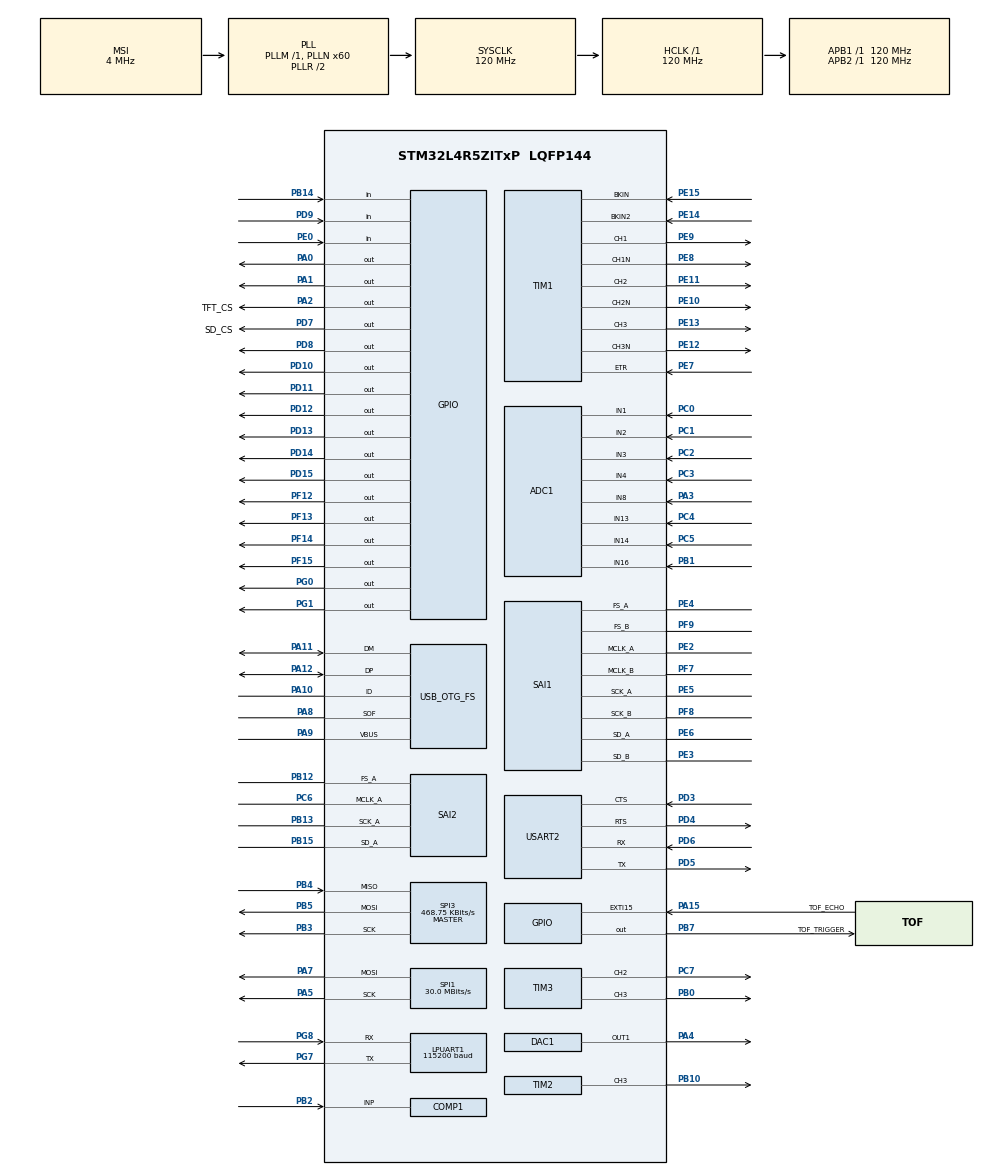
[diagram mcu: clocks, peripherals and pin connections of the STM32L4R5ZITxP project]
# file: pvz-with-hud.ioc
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ADC1.Channel-0\#ChannelRegularConversion=ADC_CHANNEL_1
ADC1.NbrOfConversionFlag=1
ADC1.OffsetNumber-0\#ChannelRegularConversion=ADC_OFFSET_NONE
ADC1.Rank-0\#ChannelRegularConversion=1
ADC1.SamplingTime-0\#ChannelRegularConversion=ADC_SAMPLETIME_2CYCLES_5
ADC1.master=1
DAC1.DAC_Trigger-DAC_OUT1=DAC_TRIGGER_T6_TRGO
Dma.DAC1_CH1.4.Direction=DMA_MEMORY_TO_PERIPH
Dma.DAC1_CH1.4.EventEnable=DISABLE
Dma.DAC1_CH1.4.Instance=DMA1_Channel5
Dma.DAC1_CH1.4.MemDataAlignment=DMA_MDATAALIGN_HALFWORD
Dma.DAC1_CH1.4.MemInc=DMA_MINC_ENABLE
Dma.DAC1_CH1.4.Mode=DMA_CIRCULAR
Dma.DAC1_CH1.4.PeriphDataAlignment=DMA_PDATAALIGN_HALFWORD
Dma.DAC1_CH1.4.PeriphInc=DMA_PINC_DISABLE
Dma.DAC1_CH1.4.Polarity=HAL_DMAMUX_REQUEST_GEN_RISING
Dma.DAC1_CH1.4.Priority=DMA_PRIORITY_HIGH
Dma.DAC1_CH1.4.RequestNumber=1
Dma.DAC1_CH1.4.SignalID=NONE
Dma.DAC1_CH1.4.SyncEnable=DISABLE
Dma.DAC1_CH1.4.SyncPolarity=HAL_DMAMUX_SYNC_NO_EVENT
Dma.DAC1_CH1.4.SyncRequestNumber=1
Dma.DAC1_CH1.4.SyncSignalID=NONE
Dma.LPUART1_RX.1.Direction=DMA_PERIPH_TO_MEMORY
Dma.LPUART1_RX.1.EventEnable=DISABLE
Dma.LPUART1_RX.1.Instance=DMA1_Channel2
Dma.LPUART1_RX.1.MemDataAlignment=DMA_MDATAALIGN_BYTE
Dma.LPUART1_RX.1.MemInc=DMA_MINC_ENABLE
Dma.LPUART1_RX.1.Mode=DMA_NORMAL
Dma.LPUART1_RX.1.PeriphDataAlignment=DMA_PDATAALIGN_BYTE
Dma.LPUART1_RX.1.PeriphInc=DMA_PINC_DISABLE
Dma.LPUART1_RX.1.Polarity=HAL_DMAMUX_REQUEST_GEN_RISING
Dma.LPUART1_RX.1.Priority=DMA_PRIORITY_MEDIUM
Dma.LPUART1_RX.1.RequestNumber=1
Dma.LPUART1_RX.1.SignalID=NONE
Dma.LPUART1_RX.1.SyncEnable=DISABLE
Dma.LPUART1_RX.1.SyncPolarity=HAL_DMAMUX_SYNC_NO_EVENT
Dma.LPUART1_RX.1.SyncRequestNumber=1
Dma.LPUART1_RX.1.SyncSignalID=NONE
Dma.Request0=SPI1_TX
Dma.Request1=LPUART1_RX
Dma.Request2=SPI3_RX
Dma.Request3=SPI3_TX
Dma.Request4=DAC1_CH1
Dma.SPI1_TX.0.Direction=DMA_MEMORY_TO_PERIPH
Dma.SPI1_TX.0.EventEnable=DISABLE
Dma.SPI1_TX.0.Instance=DMA1_Channel1
Dma.SPI1_TX.0.MemDataAlignment=DMA_MDATAALIGN_BYTE
Dma.SPI1_TX.0.MemInc=DMA_MINC_ENABLE
Dma.SPI1_TX.0.Mode=DMA_NORMAL
Dma.SPI1_TX.0.PeriphDataAlignment=DMA_PDATAALIGN_BYTE
Dma.SPI1_TX.0.PeriphInc=DMA_PINC_DISABLE
Dma.SPI1_TX.0.Polarity=HAL_DMAMUX_REQUEST_GEN_RISING
Dma.SPI1_TX.0.Priority=DMA_PRIORITY_HIGH
Dma.SPI1_TX.0.RequestNumber=1
Dma.SPI1_TX.0.SignalID=NONE
Dma.SPI1_TX.0.SyncEnable=DISABLE
Dma.SPI1_TX.0.SyncPolarity=HAL_DMAMUX_SYNC_NO_EVENT
Dma.SPI1_TX.0.SyncRequestNumber=1
Dma.SPI1_TX.0.SyncSignalID=NONE
Dma.SPI3_RX.2.Direction=DMA_PERIPH_TO_MEMORY
Dma.SPI3_RX.2.EventEnable=DISABLE
Dma.SPI3_RX.2.Instance=DMA1_Channel3
Dma.SPI3_RX.2.MemDataAlignment=DMA_MDATAALIGN_BYTE
Dma.SPI3_RX.2.MemInc=DMA_MINC_ENABLE
Dma.SPI3_RX.2.Mode=DMA_NORMAL
Dma.SPI3_RX.2.PeriphDataAlignment=DMA_PDATAALIGN_BYTE
Dma.SPI3_RX.2.PeriphInc=DMA_PINC_DISABLE
Dma.SPI3_RX.2.Polarity=HAL_DMAMUX_REQUEST_GEN_RISING
Dma.SPI3_RX.2.Priority=DMA_PRIORITY_VERY_HIGH
Dma.SPI3_RX.2.RequestNumber=1
Dma.SPI3_RX.2.SignalID=NONE
Dma.SPI3_RX.2.SyncEnable=DISABLE
Dma.SPI3_RX.2.SyncPolarity=HAL_DMAMUX_SYNC_NO_EVENT
Dma.SPI3_RX.2.SyncRequestNumber=1
Dma.SPI3_RX.2.SyncSignalID=NONE
Dma.SPI3_TX.3.Direction=DMA_MEMORY_TO_PERIPH
Dma.SPI3_TX.3.EventEnable=DISABLE
Dma.SPI3_TX.3.Instance=DMA1_Channel4
Dma.SPI3_TX.3.MemDataAlignment=DMA_MDATAALIGN_BYTE
Dma.SPI3_TX.3.MemInc=DMA_MINC_ENABLE
Dma.SPI3_TX.3.Mode=DMA_NORMAL
Dma.SPI3_TX.3.PeriphDataAlignment=DMA_PDATAALIGN_BYTE
Dma.SPI3_TX.3.PeriphInc=DMA_PINC_DISABLE
Dma.SPI3_TX.3.Polarity=HAL_DMAMUX_REQUEST_GEN_RISING
Dma.SPI3_TX.3.Priority=DMA_PRIORITY_HIGH
Dma.SPI3_TX.3.RequestNumber=1
Dma.SPI3_TX.3.SignalID=NONE
Dma.SPI3_TX.3.SyncEnable=DISABLE
Dma.SPI3_TX.3.SyncPolarity=HAL_DMAMUX_SYNC_NO_EVENT
Dma.SPI3_TX.3.SyncRequestNumber=1
Dma.SPI3_TX.3.SyncSignalID=NONE
FATFS._USE_LFN=1
LPUART1.BaudRate=115200
LPUART1.WordLength=UART_WORDLENGTH_8B
Mcu.Family=STM32L4
Mcu.Name=STM32L4R5ZITxP
Mcu.Package=LQFP144
NVIC.DMA1_Channel1_IRQn=true\:0\:0\:false\:false\:true\:false\:true\:true
NVIC.DMA1_Channel2_IRQn=true\:0\:0\:false\:false\:true\:false\:true\:true
NVIC.DMA1_Channel3_IRQn=true\:0\:0\:false\:false\:true\:false\:true\:true
NVIC.DMA1_Channel4_IRQn=true\:0\:0\:false\:false\:true\:false\:true\:true
NVIC.DMA1_Channel5_IRQn=true\:1\:0\:true\:false\:true\:false\:true\:true
NVIC.EXTI15_10_IRQn=true\:0\:0\:false\:false\:true\:true\:true\:true
NVIC.LPUART1_IRQn=true\:0\:0\:false\:false\:true\:true\:true\:true
NVIC.PriorityGroup=NVIC_PRIORITYGROUP_4
NVIC.SPI1_IRQn=true\:0\:0\:false\:false\:true\:true\:true\:true
NVIC.SPI3_IRQn=true\:0\:0\:false\:false\:true\:true\:true\:true
NVIC.TIM1_BRK_TIM15_IRQn=true\:0\:0\:false\:false\:true\:true\:true\:true
NVIC.TIM6_DAC_IRQn=true\:0\:0\:false\:false\:true\:true\:true\:true
PA0.Signal=GPIO_Output
PA1.Signal=GPIO_Output
PA10.Mode=OTG/Dual_Role_Device
PA10.Signal=USB_OTG_FS_ID
PA11.Mode=OTG/Dual_Role_Device
PA11.Signal=USB_OTG_FS_DM
PA12.Mode=OTG/Dual_Role_Device
PA12.Signal=USB_OTG_FS_DP
PA13\ (JTMS/SWDIO).Mode=Serial_Wire
PA13\ (JTMS/SWDIO).Signal=SYS_JTMS-SWDIO
PA14\ (JTCK/SWCLK).Mode=Serial_Wire
PA14\ (JTCK/SWCLK).Signal=SYS_JTCK-SWCLK
PA15\ (JTDI).GPIO_Label=TOF_ECHO
PA15\ (JTDI).GPIO_ModeDefaultEXTI=GPIO_MODE_IT_RISING_FALLING
PA15\ (JTDI).Signal=GPXTI15
PA2.GPIO_Label=TFT_CS
PA2.GPIO_Speed=GPIO_SPEED_FREQ_HIGH
PA2.Signal=GPIO_Output
PA3.Signal=ADCx_IN8
PA4.Signal=COMP_DAC11_group
PA5.Mode=TX_Only_Simplex_Unidirect_Master
PA5.Signal=SPI1_SCK
PA7.Mode=TX_Only_Simplex_Unidirect_Master
PA7.Signal=SPI1_MOSI
PA8.Mode=Activate_SOF_FS
PA8.Signal=USB_OTG_FS_SOF
PA9.Mode=Activate_VBUS
PA9.Signal=USB_OTG_FS_VBUS
PB0.Signal=S_TIM3_CH3
PB1.Signal=ADCx_IN16
PB10.Signal=S_TIM2_CH3
PB12.Mode=SAI_A_MasterWithClock
PB12.Signal=SAI2_FS_A
PB13.Mode=SAI_A_MasterWithClock
PB13.Signal=SAI2_SCK_A
PB14.Signal=GPIO_Input
PB15.Mode=SAI_A_MasterWithClock
PB15.Signal=SAI2_SD_A
PB2.Mode=INP
PB2.Signal=COMP1_INP
PB3\ (JTDO/TRACESWO).Mode=Full_Duplex_Master
PB3\ (JTDO/TRACESWO).Signal=SPI3_SCK
PB4\ (NJTRST).GPIO_PuPd=GPIO_PULLUP
PB4\ (NJTRST).Mode=Full_Duplex_Master
PB4\ (NJTRST).Signal=SPI3_MISO
PB5.Mode=Full_Duplex_Master
PB5.Signal=SPI3_MOSI
PB7.GPIO_Label=TOF_TRIGGER
PB7.Signal=GPIO_Output
PC0.Signal=ADCx_IN1
PC1.Signal=ADCx_IN2
PC13.Mode=SYS_WakeUp1
PC13.Signal=SYS_WKUP2
PC14-OSC32_IN\ (PC14).Mode=LSE-External-Oscillator
PC14-OSC32_IN\ (PC14).Signal=RCC_OSC32_IN
PC15-OSC32_OUT\ (PC15).Mode=LSE-External-Oscillator
PC15-OSC32_OUT\ (PC15).Signal=RCC_OSC32_OUT
PC2.Signal=ADCx_IN3
PC3.Signal=ADCx_IN4
PC4.Signal=ADCx_IN13
PC5.Signal=ADCx_IN14
PC6.Mode=SAI_A_MasterWithClock
PC6.Signal=SAI2_MCLK_A
PC7.Signal=S_TIM3_CH2
PD10.GPIO_Speed=GPIO_SPEED_FREQ_VERY_HIGH
PD10.Signal=GPIO_Output
PD11.GPIO_Speed=GPIO_SPEED_FREQ_VERY_HIGH
PD11.Signal=GPIO_Output
PD12.GPIO_Speed=GPIO_SPEED_FREQ_VERY_HIGH
PD12.Signal=GPIO_Output
PD13.GPIO_Speed=GPIO_SPEED_FREQ_VERY_HIGH
PD13.Signal=GPIO_Output
PD14.GPIO_Speed=GPIO_SPEED_FREQ_VERY_HIGH
PD14.Signal=GPIO_Output
PD15.GPIO_Speed=GPIO_SPEED_FREQ_VERY_HIGH
PD15.Signal=GPIO_Output
PD3.Mode=CTS_RTS
PD3.Signal=USART2_CTS
PD4.Mode=CTS_RTS
PD4.Signal=USART2_RTS
PD5.Mode=Asynchronous
PD5.Signal=USART2_TX
PD6.Mode=Asynchronous
PD6.Signal=USART2_RX
PD7.GPIO_Label=SD_CS
PD7.GPIO_PuPd=GPIO_PULLUP
PD7.GPIO_Speed=GPIO_SPEED_FREQ_HIGH
PD7.PinState=GPIO_PIN_SET
PD7.Signal=GPIO_Output
PD8.GPIO_Speed=GPIO_SPEED_FREQ_VERY_HIGH
PD8.Signal=GPIO_Output
PD9.Signal=GPIO_Input
PE0.Signal=GPIO_Input
PE10.Mode=PWM Generation2 CH2 CH2N
PE10.Signal=TIM1_CH2N
PE11.Signal=S_TIM1_CH2
PE12.Mode=PWM Generation3 CH3 CH3N
PE12.Signal=TIM1_CH3N
PE13.Signal=S_TIM1_CH3
PE14.Mode=Activate-Break-Input-2
PE14.Signal=TIM1_BKIN2
PE15.Mode=Activate-Break-Input
PE15.Signal=TIM1_BKIN
PE2.Mode=SAI_A_MasterWithClock
PE2.Signal=SAI1_MCLK_A
PE3.Mode=SAI_B_MasterWithClock
PE3.Signal=SAI1_SD_B
PE4.Mode=SAI_A_MasterWithClock
PE4.Signal=SAI1_FS_A
PE5.Mode=SAI_A_MasterWithClock
PE5.Signal=SAI1_SCK_A
PE6.Mode=SAI_A_MasterWithClock
PE6.Signal=SAI1_SD_A
PE7.Signal=S_TIM1_ETR
PE8.Mode=PWM Generation1 CH1 CH1N
PE8.Signal=TIM1_CH1N
PE9.Signal=S_TIM1_CH1
PF12.GPIO_Speed=GPIO_SPEED_FREQ_VERY_HIGH
PF12.Signal=GPIO_Output
PF13.GPIO_Speed=GPIO_SPEED_FREQ_VERY_HIGH
PF13.Signal=GPIO_Output
PF14.GPIO_Speed=GPIO_SPEED_FREQ_VERY_HIGH
PF14.Signal=GPIO_Output
PF15.GPIO_Speed=GPIO_SPEED_FREQ_VERY_HIGH
PF15.Signal=GPIO_Output
PF7.Mode=SAI_B_MasterWithClock
PF7.Signal=SAI1_MCLK_B
PF8.Mode=SAI_B_MasterWithClock
PF8.Signal=SAI1_SCK_B
PF9.Mode=SAI_B_MasterWithClock
PF9.Signal=SAI1_FS_B
PG0.GPIO_Speed=GPIO_SPEED_FREQ_VERY_HIGH
PG0.Signal=GPIO_Output
PG1.GPIO_Speed=GPIO_SPEED_FREQ_VERY_HIGH
PG1.PinState=GPIO_PIN_SET
PG1.Signal=GPIO_Output
PG7.Mode=Asynchronous
PG7.Signal=LPUART1_TX
PG8.Mode=Asynchronous
PG8.Signal=LPUART1_RX
PH0-OSC_IN\ (PH0).Mode=HSE-External-Oscillator
PH0-OSC_IN\ (PH0).Signal=RCC_OSC_IN
PH1-OSC_OUT\ (PH1).Mode=HSE-External-Oscillator
PH1-OSC_OUT\ (PH1).Signal=RCC_OSC_OUT
ProjectManager.HeapSize=0x200
ProjectManager.StackSize=0x400
ProjectManager.TargetToolchain=CMake
RCC.ADCFreq_Value=48000000
RCC.AHBFreq_Value=120000000
RCC.APB1Freq_Value=120000000
RCC.APB1TimFreq_Value=120000000
RCC.APB2Freq_Value=120000000
RCC.APB2TimFreq_Value=120000000
RCC.CortexFreq_Value=120000000
RCC.HCLKFreq_Value=120000000
RCC.HSE_VALUE=8000000
RCC.HSI48_VALUE=48000000
RCC.HSI_VALUE=16000000
RCC.MSI_VALUE=4000000
RCC.PLLN=60
RCC.PLLSAI1N=24
RCC.SYSCLKFreq_VALUE=120000000
RCC.SYSCLKSource=RCC_SYSCLKSOURCE_PLLCLK
RCC.USBFreq_Value=48000000
RCC.VCOOutputFreq_Value=240000000
SAI1.InitProtocol-SAI_A_MasterWithClock=Enable
SAI1.Instance-SAI_A_MasterWithClock=SAI$Index_Block_A
SAI1.Instance-SAI_B_MasterWithClock=SAI$Index_Block_B
SAI1.MClockEnable-SAI_A_MasterWithClock=SAI_MASTERCLOCK_ENABLE
SAI1.MClockEnable-SAI_B_MasterWithClock=SAI_MASTERCLOCK_ENABLE
SAI1.Synchro-SAI_A_MasterWithClock=SAI_ASYNCHRONOUS
SAI1.Synchro-SAI_B_MasterWithClock=SAI_ASYNCHRONOUS
SAI1.VirtualMode-SAI_A_MasterWithClock=VM_MASTER
SAI1.VirtualMode-SAI_B_MasterWithClock=VM_MASTER
SAI1.VirtualProtocol-SAI_A_BASIC=VM_BASIC_PROTOCOL
SAI2.ErrorAudioFreq-SAI_A_MasterWithClock=-2.34 %
SAI2.Instance-SAI_A_MasterWithClock=SAI$Index_Block_A
SAI2.MClockEnable-SAI_A_MasterWithClock=SAI_MASTERCLOCK_ENABLE
SAI2.RealAudioFreq-SAI_A_MasterWithClock=187.5 KHz
SAI2.Synchro-SAI_A_MasterWithClock=SAI_ASYNCHRONOUS
SAI2.VirtualMode-SAI_A_MasterWithClock=VM_MASTER
SH.ADCx_IN1.0=ADC1_IN1,IN1-Single-Ended
SH.ADCx_IN13.0=ADC1_IN13,IN13-Single-Ended
SH.ADCx_IN14.0=ADC1_IN14,IN14-Single-Ended
SH.ADCx_IN16.0=ADC1_IN16,IN16-Single-Ended
SH.ADCx_IN2.0=ADC1_IN2,IN2-Single-Ended
SH.ADCx_IN3.0=ADC1_IN3,IN3-Single-Ended
SH.ADCx_IN4.0=ADC1_IN4,IN4-Single-Ended
SH.ADCx_IN8.0=ADC1_IN8,IN8-Single-Ended
SH.COMP_DAC11_group.0=DAC1_OUT1,DAC_OUT1
SH.S_TIM1_CH1.0=TIM1_CH1,PWM Generation1 CH1 CH1N
SH.S_TIM1_CH2.0=TIM1_CH2,PWM Generation2 CH2 CH2N
SH.S_TIM1_CH3.0=TIM1_CH3,PWM Generation3 CH3 CH3N
SH.S_TIM1_ETR.0=TIM1_ETR,ETR-as-clearing-source
SH.S_TIM2_CH3.0=TIM2_CH3,PWM Generation3 CH3
SH.S_TIM3_CH2.0=TIM3_CH2,PWM Generation2 CH2
SH.S_TIM3_CH3.0=TIM3_CH3,PWM Generation3 CH3
SPI1.BaudRatePrescaler=SPI_BAUDRATEPRESCALER_4
SPI1.CalculateBaudRate=30.0 MBits/s
SPI1.DataSize=SPI_DATASIZE_8BIT
SPI1.Direction=SPI_DIRECTION_2LINES
SPI1.Mode=SPI_MODE_MASTER
SPI1.NSSPMode=SPI_NSS_PULSE_DISABLE
SPI1.VirtualType=VM_MASTER
SPI3.BaudRatePrescaler=SPI_BAUDRATEPRESCALER_256
SPI3.CalculateBaudRate=468.75 KBits/s
SPI3.DataSize=SPI_DATASIZE_8BIT
SPI3.Direction=SPI_DIRECTION_2LINES
SPI3.Mode=SPI_MODE_MASTER
SPI3.NSSPMode=SPI_NSS_PULSE_DISABLE
SPI3.VirtualType=VM_MASTER
TIM1.Channel-PWM\ Generation1\ CH1\ CH1N=TIM_CHANNEL_1
TIM1.Channel-PWM\ Generation2\ CH2\ CH2N=TIM_CHANNEL_2
TIM1.Channel-PWM\ Generation3\ CH3\ CH3N=TIM_CHANNEL_3
TIM15.Period=59
TIM15.Prescaler=119
TIM2.Channel-PWM\ Generation3\ CH3=TIM_CHANNEL_3
TIM2.Prescaler=119
TIM3.Channel-PWM\ Generation2\ CH2=TIM_CHANNEL_2
TIM3.Channel-PWM\ Generation3\ CH3=TIM_CHANNEL_3
TIM6.Period=99
TIM6.Prescaler=74
TIM6.TIM_MasterOutputTrigger=TIM_TRGO_UPDATE
USART2.VirtualMode-Asynchronous=VM_ASYNC
VP_COMP1_VS_VREFINT.Mode=VREFINT
VP_FATFS_VS_Generic.Mode=User_defined
VP_SAI1_VP_$IpInstance_SAIA_SAI_BASIC.Mode=SAI_A_BASIC
VP_TIM15_VS_ClockSourceINT.Mode=Internal
VP_TIM2_VS_ClockSourceINT.Mode=Internal
VP_TIM6_VS_ClockSourceINT.Mode=Enable_Timer
board=NUCLEO-L4R5ZI-P

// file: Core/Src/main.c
/* USER CODE BEGIN Header */
/**
 ******************************************************************************
 * @file           : main.c
 * @brief          : Main program body
 ******************************************************************************
 * @attention
 *
 * Copyright (c) 2026 STMicroelectronics.
 * All rights reserved.
 *
 * This software is licensed under terms that can be found in the LICENSE file
 * in the root directory of this software component.
 * If no LICENSE file comes with this software, it is provided AS-IS.
 *
 ******************************************************************************
 */
/* USER CODE END Header */
#include "main.h"
#include "fatfs.h"

/* USER CODE BEGIN Includes */
#include "app.h"
#include "ff.h"
#include "frame_pacing.h"
#include "hub75.h"
#include "input.h"
#include "presentation.h"
#include "pvz_config.h"

#include "ili9488.h"
#include "speaker.h"
#include "stm32l4xx_hal.h"
#include "tof_sensor.h"

#include <stdbool.h>

#include "pvz_frontend.h"
#include "pvz_uart_rx.h"
/* USER CODE END Includes */

ADC_HandleTypeDef hadc1;

COMP_HandleTypeDef hcomp1;

DAC_HandleTypeDef hdac1;
DMA_HandleTypeDef hdma_dac1_ch1;

UART_HandleTypeDef hlpuart1;
UART_HandleTypeDef huart2;
DMA_HandleTypeDef hdma_lpuart1_rx;

SAI_HandleTypeDef hsai_BlockB1;
SAI_HandleTypeDef hsai_BlockA1;
SAI_HandleTypeDef hsai_BlockA2;

SPI_HandleTypeDef hspi1;
SPI_HandleTypeDef hspi3;
DMA_HandleTypeDef hdma_spi1_tx;
DMA_HandleTypeDef hdma_spi3_rx;
DMA_HandleTypeDef hdma_spi3_tx;

TIM_HandleTypeDef htim1;
TIM_HandleTypeDef htim2;
TIM_HandleTypeDef htim3;
TIM_HandleTypeDef htim6;
TIM_HandleTypeDef htim15;

/* USER CODE BEGIN PV */
#if defined(__GNUC__)
#define RAM3_BSS __attribute__((section(".ram3_bss")))
#else
#define RAM3_BSS
#endif

// Keep the large software framebuffers out of the main SRAM stack/BSS bank.
static RAM3_BSS RenderView render_view;
static AppContext app;
static RenderData render_data;
static PvzFrontendState pvz_frontend;

/* USER CODE END PV */

void SystemClock_Config(void);
void PeriphCommonClock_Config(void);
static void MX_GPIO_Init(void);
static void MX_DMA_Init(void);
static void MX_ADC1_Init(void);
static void MX_COMP1_Init(void);
static void MX_LPUART1_UART_Init(void);
static void MX_USART2_UART_Init(void);
static void MX_SAI1_Init(void);
static void MX_SAI2_Init(void);
static void MX_SPI1_Init(void);
static void MX_SPI3_Init(void);
static void MX_TIM1_Init(void);
static void MX_TIM2_Init(void);
static void MX_TIM3_Init(void);
static void MX_TIM15_Init(void);
static void MX_USB_OTG_FS_USB_Init(void);
static void MX_DAC1_Init(void);
static void MX_TIM6_Init(void);

/* USER CODE BEGIN 0 */
enum {
	HUD_UPLOAD_BAND_HEIGHT = 12,
	HUD_PALETTE_COUNT = RENDER_PALETTE_ART_8 + 1,
	TOF_TRIGGER_PULSE_US = 15,
	TOF_MEASUREMENT_PERIOD_US = 70000,
};

FATFS SDFatFS;

static uint8_t hud_upload_buffer[PVZ_MAX_HUD_WIDTH * HUD_UPLOAD_BAND_HEIGHT * 3];
static uint8_t hud_palette_rgb666[256][3];
static bool hud_palette_rgb666_initialized = false;
static ToFSensor tof_sensor;
static uint32_t tof_next_measurement_us = 0;

static int min_int(int a, int b) { return a < b ? a : b; }

static uint32_t frame_timer_now_us(void) { return __HAL_TIM_GET_COUNTER(&htim2); }

static uint32_t frame_timer_elapsed_us(uint32_t start_us, uint32_t end_us) { return end_us - start_us; }

static bool frame_deadline_reached_us(uint32_t now_us, uint32_t deadline_us) {
	return (int32_t)(now_us - deadline_us) >= 0;
}

static void busy_wait_us(uint32_t duration_us) {
	const uint32_t start_us = frame_timer_now_us();
	while (frame_timer_elapsed_us(start_us, frame_timer_now_us()) < duration_us) {
		__NOP();
	}
}

static void wait_for_frame_deadline_ms(uint32_t deadline_ms) {
	while (1) {
		const uint32_t now_ms = HAL_GetTick();
		const int32_t remaining_ms = (int32_t)(deadline_ms - now_ms);

		if (remaining_ms <= 0) {
			return;
		}

		if (remaining_ms > 1) {
			HAL_Delay((uint32_t)(remaining_ms - 1));
			continue;
		}

		__NOP();
	}
}

static void rgb565_to_rgb666_bytes(uint16_t color, uint8_t rgb[3]) {
	rgb[0] = (uint8_t)(((color >> 11) & 0x1Fu) << 3);
	rgb[1] = (uint8_t)(((color >> 5) & 0x3Fu) << 2);
	rgb[2] = (uint8_t)((color & 0x1Fu) << 3);
}

static void init_hud_palette_rgb666(void) {
	if (hud_palette_rgb666_initialized) {
		return;
	}

	for (int palette = 0; palette < HUD_PALETTE_COUNT; ++palette) {
		rgb565_to_rgb666_bytes(presentation_palette_to_rgb565((RenderPalette)palette), hud_palette_rgb666[palette]);
	}

	hud_palette_rgb666_initialized = true;
}

static void init_hub75_palette(void) {
	for (int palette = 0; palette < HUD_PALETTE_COUNT; ++palette) {
		hub75_set_palette_rgb565((uint8_t)palette, presentation_palette_to_rgb565((RenderPalette)palette));
	}
}

static void tof_poll_sensor(uint32_t now_us) {
	tof_sensor_update(&tof_sensor, now_us);

	if (frame_deadline_reached_us(now_us, tof_next_measurement_us)) {
		HAL_GPIO_WritePin(TOF_TRIGGER_GPIO_Port, TOF_TRIGGER_Pin, GPIO_PIN_SET);
		busy_wait_us(TOF_TRIGGER_PULSE_US);
		HAL_GPIO_WritePin(TOF_TRIGGER_GPIO_Port, TOF_TRIGGER_Pin, GPIO_PIN_RESET);
		tof_next_measurement_us = now_us + TOF_MEASUREMENT_PERIOD_US;
	}
}

static void upload_to_hud(const RenderView *view) {
	if (view == NULL || view->hud_dirty_rects.count <= 0 || view->hud_width <= 0 || view->hud_height <= 0) {
		return;
	}

	init_hud_palette_rgb666();

	for (int rect_index = 0; rect_index < view->hud_dirty_rects.count; ++rect_index) {
		IntRect rect = view->hud_dirty_rects.rects[rect_index];
		if (rect.x < 0) {
			rect.w += rect.x;
			rect.x = 0;
		}
		if (rect.y < 0) {
			rect.h += rect.y;
			rect.y = 0;
		}
		if (rect.x + rect.w > view->hud_width) {
			rect.w = view->hud_width - rect.x;
		}
		if (rect.y + rect.h > view->hud_height) {
			rect.h = view->hud_height - rect.y;
		}
		if (rect.w <= 0 || rect.h <= 0) {
			continue;
		}

		for (int band_y = 0; band_y < rect.h; band_y += HUD_UPLOAD_BAND_HEIGHT) {
			const int band_height = min_int(HUD_UPLOAD_BAND_HEIGHT, rect.h - band_y);
			const uint8_t *src_row = &view->hud_pixels[(rect.y + band_y) * view->hud_width + rect.x];
			uint8_t *dst = hud_upload_buffer;

			for (int row = 0; row < band_height; ++row) {
				const uint8_t *src = src_row + row * view->hud_width;
				for (int col = 0; col < rect.w; ++col) {
					const uint8_t *rgb = hud_palette_rgb666[src[col]];
					*dst++ = rgb[0];
					*dst++ = rgb[1];
					*dst++ = rgb[2];
				}
			}

			ILI9488_DrawImage((uint16_t)rect.x, (uint16_t)(rect.y + band_y), (uint16_t)rect.w, (uint16_t)band_height,
							  hud_upload_buffer);
		}
	}
}

void HAL_GPIO_EXTI_Callback(uint16_t GPIO_Pin) {
	if (GPIO_Pin == TOF_ECHO_Pin) {
		const bool level_high = HAL_GPIO_ReadPin(TOF_ECHO_GPIO_Port, TOF_ECHO_Pin) == GPIO_PIN_SET;
		tof_sensor_handle_echo_edge(&tof_sensor, frame_timer_now_us(), level_high);
	}
}
/* USER CODE END 0 */

int main(void) {

	/* MCU Configuration--------------------------------------------------------*/

	/* Reset of all peripherals, Initializes the Flash interface and the Systick. */
	HAL_Init();

	/* Configure the system clock */
	SystemClock_Config();

	/* Configure the peripherals common clocks */
	PeriphCommonClock_Config();

	/* Initialize all configured peripherals */
	MX_GPIO_Init();
	MX_DMA_Init();
	MX_ADC1_Init();
	MX_COMP1_Init();
	MX_LPUART1_UART_Init();
	MX_USART2_UART_Init();
	MX_SAI1_Init();
	MX_SAI2_Init();
	MX_SPI1_Init();
	MX_SPI3_Init();
	MX_TIM1_Init();
	MX_TIM2_Init();
	MX_TIM3_Init();
	MX_TIM15_Init();
	MX_USB_OTG_FS_USB_Init();
	MX_FATFS_Init();
	MX_DAC1_Init();
	MX_TIM6_Init();
	/* USER CODE BEGIN 2 */
	ILI9488_Init();
	ILI9488_SetRotation(3);

	// Mount sd
	(void)f_mount(&SDFatFS, "", 1);

	GameConfig config = pvz_make_default_config();
	// config.start_with_demo_layout = true;

	app_init(&app, &config);
	pvz_frontend_init(&pvz_frontend, &app.config);

	PvzFrontendSnapshot frontend_snapshot = {0};
	uint32_t frontend_snapshot_generation = 0u;
	(void)pvz_uart_rx_init(&hlpuart1, &app.config);
	pvz_frontend_ingest_snapshot(&pvz_frontend, &frontend_snapshot, 0, false);
	pvz_frontend_export_presentation_state(&pvz_frontend, &app.play_state.game, &app.play_presentation);

	render_view_init(&render_view, config.board_x_resolution, config.board_y_resolution, config.hud_x_resolution,
					 config.hud_y_resolution);
	render_data_init(&render_data);

	app_prerender(&app, &render_view, &render_data);
	upload_to_hud(&render_view);

	hub75_init();
	init_hub75_palette();
	hub75_upload_indexed_64x32(render_view.board_pixels, (uint16_t)render_view.board_width);
	hub75_start();

	HAL_NVIC_SetPriority(TIM1_BRK_TIM15_IRQn, 0, 0);
	HAL_NVIC_SetPriority(DMA1_Channel5_IRQn, 1, 0);
	/* USER CODE END 2 */

	/* Infinite loop */
	/* USER CODE BEGIN WHILE */
	HAL_TIM_Base_Start(&htim2);
	__HAL_TIM_SET_COUNTER(&htim2, 0);
	tof_sensor_init(&tof_sensor);
	tof_next_measurement_us = frame_timer_now_us();

	AUDIO_Play();

	const uint32_t target_frame_ms = frame_pacing_target_frame_ms(app.config.fixed_dt);
	uint32_t previous_frame_start_ms = HAL_GetTick() - target_frame_ms;
	uint32_t next_frame_deadline_ms = HAL_GetTick() + target_frame_ms;

	volatile uint32_t work_duration_us;
	(void)work_duration_us;
	while (1) {
		const uint32_t frame_start_ms = HAL_GetTick();
		const uint32_t frame_start_us = frame_timer_now_us();
		const float frame_dt =
			frame_pacing_frame_dt_from_elapsed_ms(frame_start_ms - previous_frame_start_ms, app.config.fixed_dt);
		previous_frame_start_ms = frame_start_ms;
		bool hud_uploaded_from_prerender = false;

		InputFrame input;
		input_frame_reset(&input);
		tof_poll_sensor(frame_start_us);
		uint32_t latest_snapshot_generation = frontend_snapshot_generation;
		const bool have_uart_snapshot = pvz_uart_rx_read_latest(&frontend_snapshot, NULL, &latest_snapshot_generation);
		const bool snapshot_is_new = have_uart_snapshot && latest_snapshot_generation != frontend_snapshot_generation;
		if (snapshot_is_new) {
			frontend_snapshot_generation = latest_snapshot_generation;
		}
		frontend_snapshot.hand_present = tof_sensor_hand_present(&tof_sensor);
		pvz_frontend_ingest_snapshot(&pvz_frontend, &frontend_snapshot, frame_start_ms, snapshot_is_new);
		const bool play_scene_was_active = app.active_scene_id == SCENE_ID_PLAY;
		pvz_frontend_build_input(&pvz_frontend, &app.play_state.game, &input, app.active_scene_id);

		// Update and render
		const UpdateResult update_result = app_update(&app, &input, frame_dt);
		pvz_frontend_post_update(&pvz_frontend, &app.play_state.prev_game_state, &app.play_state.game, frame_dt,
								 play_scene_was_active);
		pvz_frontend_export_presentation_state(&pvz_frontend, &app.play_state.game, &app.play_presentation);
		if (update_result == UPDATE_CHANGED_SCENE) {
			app_prerender(&app, &render_view, &render_data);
			upload_to_hud(&render_view);
			hud_uploaded_from_prerender = true;
		} else {
			app_render(&app, &render_view, &render_data);
		}

		hub75_upload_indexed_64x32(render_view.board_pixels, (uint16_t)render_view.board_width);
		if (!hud_uploaded_from_prerender) {
			upload_to_hud(&render_view);
		}

		AUDIO_Task();

		/* USER CODE END WHILE */

		/* USER CODE BEGIN 3 */
		// Measure actual work time (Profiling)
		const uint32_t work_end_us = frame_timer_now_us();
		work_duration_us = frame_timer_elapsed_us(frame_start_us, work_end_us);

		wait_for_frame_deadline_ms(next_frame_deadline_ms);
		next_frame_deadline_ms = frame_pacing_next_deadline_ms(next_frame_deadline_ms, target_frame_ms, HAL_GetTick());
	}
	/* USER CODE END 3 */
}

void SystemClock_Config(void) {
	RCC_OscInitTypeDef RCC_OscInitStruct = {0};
	RCC_ClkInitTypeDef RCC_ClkInitStruct = {0};

	/** Configure the main internal regulator output voltage
	 */
	if (HAL_PWREx_ControlVoltageScaling(PWR_REGULATOR_VOLTAGE_SCALE1_BOOST) != HAL_OK) {
		Error_Handler();
	}

	/** Configure LSE Drive Capability
	 */
	HAL_PWR_EnableBkUpAccess();
	__HAL_RCC_LSEDRIVE_CONFIG(RCC_LSEDRIVE_LOW);

	/** Initializes the RCC Oscillators according to the specified parameters
	 * in the RCC_OscInitTypeDef structure.
	 */
	RCC_OscInitStruct.OscillatorType = RCC_OSCILLATORTYPE_LSE | RCC_OSCILLATORTYPE_MSI;
	RCC_OscInitStruct.LSEState = RCC_LSE_ON;
	RCC_OscInitStruct.MSIState = RCC_MSI_ON;
	RCC_OscInitStruct.MSICalibrationValue = 0;
	RCC_OscInitStruct.MSIClockRange = RCC_MSIRANGE_6;
	RCC_OscInitStruct.PLL.PLLState = RCC_PLL_ON;
	RCC_OscInitStruct.PLL.PLLSource = RCC_PLLSOURCE_MSI;
	RCC_OscInitStruct.PLL.PLLM = 1;
	RCC_OscInitStruct.PLL.PLLN = 60;
	RCC_OscInitStruct.PLL.PLLP = RCC_PLLP_DIV2;
	RCC_OscInitStruct.PLL.PLLQ = RCC_PLLQ_DIV2;
	RCC_OscInitStruct.PLL.PLLR = RCC_PLLR_DIV2;
	if (HAL_RCC_OscConfig(&RCC_OscInitStruct) != HAL_OK) {
		Error_Handler();
	}

	/** Initializes the CPU, AHB and APB buses clocks
	 */
	RCC_ClkInitStruct.ClockType = RCC_CLOCKTYPE_HCLK | RCC_CLOCKTYPE_SYSCLK | RCC_CLOCKTYPE_PCLK1 | RCC_CLOCKTYPE_PCLK2;
	RCC_ClkInitStruct.SYSCLKSource = RCC_SYSCLKSOURCE_PLLCLK;
	RCC_ClkInitStruct.AHBCLKDivider = RCC_SYSCLK_DIV1;
	RCC_ClkInitStruct.APB1CLKDivider = RCC_HCLK_DIV1;
	RCC_ClkInitStruct.APB2CLKDivider = RCC_HCLK_DIV1;

	if (HAL_RCC_ClockConfig(&RCC_ClkInitStruct, FLASH_LATENCY_5) != HAL_OK) {
		Error_Handler();
	}

	/** Enable MSI Auto calibration
	 */
	HAL_RCCEx_EnableMSIPLLMode();
}

void PeriphCommonClock_Config(void) {
	RCC_PeriphCLKInitTypeDef PeriphClkInit = {0};

	/** Initializes the peripherals clock
	 */
	PeriphClkInit.PeriphClockSelection =
		RCC_PERIPHCLK_SAI1 | RCC_PERIPHCLK_SAI2 | RCC_PERIPHCLK_USB | RCC_PERIPHCLK_ADC;
	PeriphClkInit.Sai1ClockSelection = RCC_SAI1CLKSOURCE_PLLSAI1;
	PeriphClkInit.Sai2ClockSelection = RCC_SAI2CLKSOURCE_PLLSAI1;
	PeriphClkInit.AdcClockSelection = RCC_ADCCLKSOURCE_PLLSAI1;
	PeriphClkInit.UsbClockSelection = RCC_USBCLKSOURCE_PLLSAI1;
	PeriphClkInit.PLLSAI1.PLLSAI1Source = RCC_PLLSOURCE_MSI;
	PeriphClkInit.PLLSAI1.PLLSAI1M = 1;
	PeriphClkInit.PLLSAI1.PLLSAI1N = 24;
	PeriphClkInit.PLLSAI1.PLLSAI1P = RCC_PLLP_DIV2;
	PeriphClkInit.PLLSAI1.PLLSAI1Q = RCC_PLLQ_DIV2;
	PeriphClkInit.PLLSAI1.PLLSAI1R = RCC_PLLR_DIV2;
	PeriphClkInit.PLLSAI1.PLLSAI1ClockOut = RCC_PLLSAI1_SAI1CLK | RCC_PLLSAI1_48M2CLK | RCC_PLLSAI1_ADC1CLK;
	if (HAL_RCCEx_PeriphCLKConfig(&PeriphClkInit) != HAL_OK) {
		Error_Handler();
	}
}

static void MX_ADC1_Init(void) {

	ADC_ChannelConfTypeDef sConfig = {0};

	/** Common config
	 */
	hadc1.Instance = ADC1;
	hadc1.Init.ClockPrescaler = ADC_CLOCK_ASYNC_DIV1;
	hadc1.Init.Resolution = ADC_RESOLUTION_12B;
	hadc1.Init.DataAlign = ADC_DATAALIGN_RIGHT;
	hadc1.Init.ScanConvMode = ADC_SCAN_DISABLE;
	hadc1.Init.EOCSelection = ADC_EOC_SINGLE_CONV;
	hadc1.Init.LowPowerAutoWait = DISABLE;
	hadc1.Init.ContinuousConvMode = DISABLE;
	hadc1.Init.NbrOfConversion = 1;
	hadc1.Init.DiscontinuousConvMode = DISABLE;
	hadc1.Init.ExternalTrigConv = ADC_SOFTWARE_START;
	hadc1.Init.ExternalTrigConvEdge = ADC_EXTERNALTRIGCONVEDGE_NONE;
	hadc1.Init.DMAContinuousRequests = DISABLE;
	hadc1.Init.Overrun = ADC_OVR_DATA_PRESERVED;
	hadc1.Init.OversamplingMode = DISABLE;
	if (HAL_ADC_Init(&hadc1) != HAL_OK) {
		Error_Handler();
	}

	/** Configure Regular Channel
	 */
	sConfig.Channel = ADC_CHANNEL_1;
	sConfig.Rank = ADC_REGULAR_RANK_1;
	sConfig.SamplingTime = ADC_SAMPLETIME_2CYCLES_5;
	sConfig.SingleDiff = ADC_SINGLE_ENDED;
	sConfig.OffsetNumber = ADC_OFFSET_NONE;
	sConfig.Offset = 0;
	if (HAL_ADC_ConfigChannel(&hadc1, &sConfig) != HAL_OK) {
		Error_Handler();
	}
}

static void MX_COMP1_Init(void) {

	hcomp1.Instance = COMP1;
	hcomp1.Init.InvertingInput = COMP_INPUT_MINUS_VREFINT;
	hcomp1.Init.NonInvertingInput = COMP_INPUT_PLUS_IO2;
	hcomp1.Init.OutputPol = COMP_OUTPUTPOL_NONINVERTED;
	hcomp1.Init.Hysteresis = COMP_HYSTERESIS_NONE;
	hcomp1.Init.BlankingSrce = COMP_BLANKINGSRC_NONE;
	hcomp1.Init.Mode = COMP_POWERMODE_HIGHSPEED;
	hcomp1.Init.WindowMode = COMP_WINDOWMODE_DISABLE;
	hcomp1.Init.TriggerMode = COMP_TRIGGERMODE_NONE;
	if (HAL_COMP_Init(&hcomp1) != HAL_OK) {
		Error_Handler();
	}
}

static void MX_DAC1_Init(void) {

	DAC_ChannelConfTypeDef sConfig = {0};

	/** DAC Initialization
	 */
	hdac1.Instance = DAC1;
	if (HAL_DAC_Init(&hdac1) != HAL_OK) {
		Error_Handler();
	}

	/** DAC channel OUT1 config
	 */
	sConfig.DAC_SampleAndHold = DAC_SAMPLEANDHOLD_DISABLE;
	sConfig.DAC_Trigger = DAC_TRIGGER_T6_TRGO;
	sConfig.DAC_HighFrequency = DAC_HIGH_FREQUENCY_INTERFACE_MODE_ABOVE_80MHZ;
	sConfig.DAC_OutputBuffer = DAC_OUTPUTBUFFER_ENABLE;
	sConfig.DAC_ConnectOnChipPeripheral = DAC_CHIPCONNECT_DISABLE;
	sConfig.DAC_UserTrimming = DAC_TRIMMING_FACTORY;
	if (HAL_DAC_ConfigChannel(&hdac1, &sConfig, DAC_CHANNEL_1) != HAL_OK) {
		Error_Handler();
	}
}

static void MX_LPUART1_UART_Init(void) {

	hlpuart1.Instance = LPUART1;
	hlpuart1.Init.BaudRate = 115200;
	hlpuart1.Init.WordLength = UART_WORDLENGTH_8B;
	hlpuart1.Init.StopBits = UART_STOPBITS_1;
	hlpuart1.Init.Parity = UART_PARITY_NONE;
	hlpuart1.Init.Mode = UART_MODE_TX_RX;
	hlpuart1.Init.HwFlowCtl = UART_HWCONTROL_NONE;
	hlpuart1.Init.OneBitSampling = UART_ONE_BIT_SAMPLE_DISABLE;
	hlpuart1.Init.ClockPrescaler = UART_PRESCALER_DIV1;
	hlpuart1.AdvancedInit.AdvFeatureInit = UART_ADVFEATURE_NO_INIT;
	hlpuart1.FifoMode = UART_FIFOMODE_DISABLE;
	if (HAL_UART_Init(&hlpuart1) != HAL_OK) {
		Error_Handler();
	}
	if (HAL_UARTEx_SetTxFifoThreshold(&hlpuart1, UART_TXFIFO_THRESHOLD_1_8) != HAL_OK) {
		Error_Handler();
	}
	if (HAL_UARTEx_SetRxFifoThreshold(&hlpuart1, UART_RXFIFO_THRESHOLD_1_8) != HAL_OK) {
		Error_Handler();
	}
	if (HAL_UARTEx_DisableFifoMode(&hlpuart1) != HAL_OK) {
		Error_Handler();
	}
}

static void MX_USART2_UART_Init(void) {

	huart2.Instance = USART2;
	huart2.Init.BaudRate = 115200;
	huart2.Init.WordLength = UART_WORDLENGTH_8B;
	huart2.Init.StopBits = UART_STOPBITS_1;
	huart2.Init.Parity = UART_PARITY_NONE;
	huart2.Init.Mode = UART_MODE_TX_RX;
	huart2.Init.HwFlowCtl = UART_HWCONTROL_RTS_CTS;
	huart2.Init.OverSampling = UART_OVERSAMPLING_16;
	huart2.Init.OneBitSampling = UART_ONE_BIT_SAMPLE_DISABLE;
	huart2.Init.ClockPrescaler = UART_PRESCALER_DIV1;
	huart2.AdvancedInit.AdvFeatureInit = UART_ADVFEATURE_NO_INIT;
	if (HAL_UART_Init(&huart2) != HAL_OK) {
		Error_Handler();
	}
	if (HAL_UARTEx_SetTxFifoThreshold(&huart2, UART_TXFIFO_THRESHOLD_1_8) != HAL_OK) {
		Error_Handler();
	}
	if (HAL_UARTEx_SetRxFifoThreshold(&huart2, UART_RXFIFO_THRESHOLD_1_8) != HAL_OK) {
		Error_Handler();
	}
	if (HAL_UARTEx_DisableFifoMode(&huart2) != HAL_OK) {
		Error_Handler();
	}
}

static void MX_SAI1_Init(void) {

	hsai_BlockB1.Instance = SAI1_Block_B;
	hsai_BlockB1.Init.Protocol = SAI_FREE_PROTOCOL;
	hsai_BlockB1.Init.AudioMode = SAI_MODEMASTER_TX;
	hsai_BlockB1.Init.DataSize = SAI_DATASIZE_8;
	hsai_BlockB1.Init.FirstBit = SAI_FIRSTBIT_MSB;
	hsai_BlockB1.Init.ClockStrobing = SAI_CLOCKSTROBING_FALLINGEDGE;
	hsai_BlockB1.Init.Synchro = SAI_ASYNCHRONOUS;
	hsai_BlockB1.Init.OutputDrive = SAI_OUTPUTDRIVE_DISABLE;
	hsai_BlockB1.Init.NoDivider = SAI_MASTERDIVIDER_ENABLE;
	hsai_BlockB1.Init.MckOverSampling = SAI_MCK_OVERSAMPLING_DISABLE;
	hsai_BlockB1.Init.FIFOThreshold = SAI_FIFOTHRESHOLD_EMPTY;
	hsai_BlockB1.Init.AudioFrequency = SAI_AUDIO_FREQUENCY_192K;
	hsai_BlockB1.Init.SynchroExt = SAI_SYNCEXT_DISABLE;
	hsai_BlockB1.Init.MonoStereoMode = SAI_STEREOMODE;
	hsai_BlockB1.Init.CompandingMode = SAI_NOCOMPANDING;
	hsai_BlockB1.Init.TriState = SAI_OUTPUT_NOTRELEASED;
	hsai_BlockB1.Init.PdmInit.Activation = DISABLE;
	hsai_BlockB1.Init.PdmInit.MicPairsNbr = 0;
	hsai_BlockB1.Init.PdmInit.ClockEnable = SAI_PDM_CLOCK1_ENABLE;
	hsai_BlockB1.FrameInit.FrameLength = 8;
	hsai_BlockB1.FrameInit.ActiveFrameLength = 1;
	hsai_BlockB1.FrameInit.FSDefinition = SAI_FS_STARTFRAME;
	hsai_BlockB1.FrameInit.FSPolarity = SAI_FS_ACTIVE_LOW;
	hsai_BlockB1.FrameInit.FSOffset = SAI_FS_FIRSTBIT;
	hsai_BlockB1.SlotInit.FirstBitOffset = 0;
	hsai_BlockB1.SlotInit.SlotSize = SAI_SLOTSIZE_DATASIZE;
	hsai_BlockB1.SlotInit.SlotNumber = 1;
	hsai_BlockB1.SlotInit.SlotActive = 0x00000000;
	if (HAL_SAI_Init(&hsai_BlockB1) != HAL_OK) {
		Error_Handler();
	}
	hsai_BlockA1.Instance = SAI1_Block_A;
	hsai_BlockA1.Init.AudioMode = SAI_MODEMASTER_TX;
	hsai_BlockA1.Init.Synchro = SAI_ASYNCHRONOUS;
	hsai_BlockA1.Init.OutputDrive = SAI_OUTPUTDRIVE_DISABLE;
	hsai_BlockA1.Init.NoDivider = SAI_MASTERDIVIDER_ENABLE;
	hsai_BlockA1.Init.FIFOThreshold = SAI_FIFOTHRESHOLD_EMPTY;
	hsai_BlockA1.Init.AudioFrequency = SAI_AUDIO_FREQUENCY_192K;
	hsai_BlockA1.Init.SynchroExt = SAI_SYNCEXT_DISABLE;
	hsai_BlockA1.Init.MonoStereoMode = SAI_STEREOMODE;
	hsai_BlockA1.Init.CompandingMode = SAI_NOCOMPANDING;
	hsai_BlockA1.Init.TriState = SAI_OUTPUT_NOTRELEASED;
	if (HAL_SAI_InitProtocol(&hsai_BlockA1, SAI_I2S_STANDARD, SAI_PROTOCOL_DATASIZE_16BIT, 2) != HAL_OK) {
		Error_Handler();
	}
}

static void MX_SAI2_Init(void) {

	hsai_BlockA2.Instance = SAI2_Block_A;
	hsai_BlockA2.Init.Protocol = SAI_FREE_PROTOCOL;
	hsai_BlockA2.Init.AudioMode = SAI_MODEMASTER_TX;
	hsai_BlockA2.Init.DataSize = SAI_DATASIZE_8;
	hsai_BlockA2.Init.FirstBit = SAI_FIRSTBIT_MSB;
	hsai_BlockA2.Init.ClockStrobing = SAI_CLOCKSTROBING_FALLINGEDGE;
	hsai_BlockA2.Init.Synchro = SAI_ASYNCHRONOUS;
	hsai_BlockA2.Init.OutputDrive = SAI_OUTPUTDRIVE_DISABLE;
	hsai_BlockA2.Init.NoDivider = SAI_MASTERDIVIDER_ENABLE;
	hsai_BlockA2.Init.MckOverSampling = SAI_MCK_OVERSAMPLING_DISABLE;
	hsai_BlockA2.Init.FIFOThreshold = SAI_FIFOTHRESHOLD_EMPTY;
	hsai_BlockA2.Init.AudioFrequency = SAI_AUDIO_FREQUENCY_192K;
	hsai_BlockA2.Init.SynchroExt = SAI_SYNCEXT_DISABLE;
	hsai_BlockA2.Init.MonoStereoMode = SAI_STEREOMODE;
	hsai_BlockA2.Init.CompandingMode = SAI_NOCOMPANDING;
	hsai_BlockA2.Init.TriState = SAI_OUTPUT_NOTRELEASED;
	hsai_BlockA2.Init.PdmInit.Activation = DISABLE;
	hsai_BlockA2.Init.PdmInit.MicPairsNbr = 0;
	hsai_BlockA2.Init.PdmInit.ClockEnable = SAI_PDM_CLOCK1_ENABLE;
	hsai_BlockA2.FrameInit.FrameLength = 8;
	hsai_BlockA2.FrameInit.ActiveFrameLength = 1;
	hsai_BlockA2.FrameInit.FSDefinition = SAI_FS_STARTFRAME;
	hsai_BlockA2.FrameInit.FSPolarity = SAI_FS_ACTIVE_LOW;
	hsai_BlockA2.FrameInit.FSOffset = SAI_FS_FIRSTBIT;
	hsai_BlockA2.SlotInit.FirstBitOffset = 0;
	hsai_BlockA2.SlotInit.SlotSize = SAI_SLOTSIZE_DATASIZE;
	hsai_BlockA2.SlotInit.SlotNumber = 1;
	hsai_BlockA2.SlotInit.SlotActive = 0x00000000;
	if (HAL_SAI_Init(&hsai_BlockA2) != HAL_OK) {
		Error_Handler();
	}
}

static void MX_SPI1_Init(void) {

	/* SPI1 parameter configuration*/
	hspi1.Instance = SPI1;
	hspi1.Init.Mode = SPI_MODE_MASTER;
	hspi1.Init.Direction = SPI_DIRECTION_2LINES;
	hspi1.Init.DataSize = SPI_DATASIZE_8BIT;
	hspi1.Init.CLKPolarity = SPI_POLARITY_LOW;
	hspi1.Init.CLKPhase = SPI_PHASE_1EDGE;
	hspi1.Init.NSS = SPI_NSS_SOFT;
	hspi1.Init.BaudRatePrescaler = SPI_BAUDRATEPRESCALER_4;
	hspi1.Init.FirstBit = SPI_FIRSTBIT_MSB;
	hspi1.Init.TIMode = SPI_TIMODE_DISABLE;
	hspi1.Init.CRCCalculation = SPI_CRCCALCULATION_DISABLE;
	hspi1.Init.CRCPolynomial = 7;
	hspi1.Init.CRCLength = SPI_CRC_LENGTH_DATASIZE;
	hspi1.Init.NSSPMode = SPI_NSS_PULSE_DISABLE;
	if (HAL_SPI_Init(&hspi1) != HAL_OK) {
		Error_Handler();
	}
}

static void MX_SPI3_Init(void) {

	/* SPI3 parameter configuration*/
	hspi3.Instance = SPI3;
	hspi3.Init.Mode = SPI_MODE_MASTER;
	hspi3.Init.Direction = SPI_DIRECTION_2LINES;
	hspi3.Init.DataSize = SPI_DATASIZE_8BIT;
	hspi3.Init.CLKPolarity = SPI_POLARITY_LOW;
	hspi3.Init.CLKPhase = SPI_PHASE_1EDGE;
	hspi3.Init.NSS = SPI_NSS_SOFT;
	hspi3.Init.BaudRatePrescaler = SPI_BAUDRATEPRESCALER_256;
	hspi3.Init.FirstBit = SPI_FIRSTBIT_MSB;
	hspi3.Init.TIMode = SPI_TIMODE_DISABLE;
	hspi3.Init.CRCCalculation = SPI_CRCCALCULATION_DISABLE;
	hspi3.Init.CRCPolynomial = 7;
	hspi3.Init.CRCLength = SPI_CRC_LENGTH_DATASIZE;
	hspi3.Init.NSSPMode = SPI_NSS_PULSE_DISABLE;
	if (HAL_SPI_Init(&hspi3) != HAL_OK) {
		Error_Handler();
	}
}

static void MX_TIM1_Init(void) {

	TIM_MasterConfigTypeDef sMasterConfig = {0};
	TIMEx_BreakInputConfigTypeDef sBreakInputConfig = {0};
	TIM_OC_InitTypeDef sConfigOC = {0};
	TIM_BreakDeadTimeConfigTypeDef sBreakDeadTimeConfig = {0};

	htim1.Instance = TIM1;
	htim1.Init.Prescaler = 0;
	htim1.Init.CounterMode = TIM_COUNTERMODE_UP;
	htim1.Init.Period = 65535;
	htim1.Init.ClockDivision = TIM_CLOCKDIVISION_DIV1;
	htim1.Init.RepetitionCounter = 0;
	htim1.Init.AutoReloadPreload = TIM_AUTORELOAD_PRELOAD_DISABLE;
	if (HAL_TIM_PWM_Init(&htim1) != HAL_OK) {
		Error_Handler();
	}
	sMasterConfig.MasterOutputTrigger = TIM_TRGO_RESET;
	sMasterConfig.MasterOutputTrigger2 = TIM_TRGO2_RESET;
	sMasterConfig.MasterSlaveMode = TIM_MASTERSLAVEMODE_DISABLE;
	if (HAL_TIMEx_MasterConfigSynchronization(&htim1, &sMasterConfig) != HAL_OK) {
		Error_Handler();
	}
	sBreakInputConfig.Source = TIM_BREAKINPUTSOURCE_BKIN;
	sBreakInputConfig.Enable = TIM_BREAKINPUTSOURCE_ENABLE;
	sBreakInputConfig.Polarity = TIM_BREAKINPUTSOURCE_POLARITY_HIGH;
	if (HAL_TIMEx_ConfigBreakInput(&htim1, TIM_BREAKINPUT_BRK, &sBreakInputConfig) != HAL_OK) {
		Error_Handler();
	}
	if (HAL_TIMEx_ConfigBreakInput(&htim1, TIM_BREAKINPUT_BRK2, &sBreakInputConfig) != HAL_OK) {
		Error_Handler();
	}
	sConfigOC.OCMode = TIM_OCMODE_PWM1;
	sConfigOC.Pulse = 0;
	sConfigOC.OCPolarity = TIM_OCPOLARITY_HIGH;
	sConfigOC.OCNPolarity = TIM_OCNPOLARITY_HIGH;
	sConfigOC.OCFastMode = TIM_OCFAST_DISABLE;
	sConfigOC.OCIdleState = TIM_OCIDLESTATE_RESET;
	sConfigOC.OCNIdleState = TIM_OCNIDLESTATE_RESET;
	if (HAL_TIM_PWM_ConfigChannel(&htim1, &sConfigOC, TIM_CHANNEL_1) != HAL_OK) {
		Error_Handler();
	}
	if (HAL_TIM_PWM_ConfigChannel(&htim1, &sConfigOC, TIM_CHANNEL_2) != HAL_OK) {
		Error_Handler();
	}
	if (HAL_TIM_PWM_ConfigChannel(&htim1, &sConfigOC, TIM_CHANNEL_3) != HAL_OK) {
		Error_Handler();
	}
	sBreakDeadTimeConfig.OffStateRunMode = TIM_OSSR_ENABLE;
	sBreakDeadTimeConfig.OffStateIDLEMode = TIM_OSSI_ENABLE;
	sBreakDeadTimeConfig.LockLevel = TIM_LOCKLEVEL_OFF;
	sBreakDeadTimeConfig.DeadTime = 0;
	sBreakDeadTimeConfig.BreakState = TIM_BREAK_ENABLE;
	sBreakDeadTimeConfig.BreakPolarity = TIM_BREAKPOLARITY_HIGH;
	sBreakDeadTimeConfig.BreakFilter = 0;
	sBreakDeadTimeConfig.Break2State = TIM_BREAK2_ENABLE;
	sBreakDeadTimeConfig.Break2Polarity = TIM_BREAK2POLARITY_HIGH;
	sBreakDeadTimeConfig.Break2Filter = 0;
	sBreakDeadTimeConfig.AutomaticOutput = TIM_AUTOMATICOUTPUT_DISABLE;
	if (HAL_TIMEx_ConfigBreakDeadTime(&htim1, &sBreakDeadTimeConfig) != HAL_OK) {
		Error_Handler();
	}
	HAL_TIM_MspPostInit(&htim1);
}

static void MX_TIM2_Init(void) {

	TIM_ClockConfigTypeDef sClockSourceConfig = {0};
	TIM_MasterConfigTypeDef sMasterConfig = {0};
	TIM_OC_InitTypeDef sConfigOC = {0};

	htim2.Instance = TIM2;
	htim2.Init.Prescaler = 119;
	htim2.Init.CounterMode = TIM_COUNTERMODE_UP;
	htim2.Init.Period = 4294967295;
	htim2.Init.ClockDivision = TIM_CLOCKDIVISION_DIV1;
	htim2.Init.AutoReloadPreload = TIM_AUTORELOAD_PRELOAD_DISABLE;
	if (HAL_TIM_Base_Init(&htim2) != HAL_OK) {
		Error_Handler();
	}
	sClockSourceConfig.ClockSource = TIM_CLOCKSOURCE_INTERNAL;
	if (HAL_TIM_ConfigClockSource(&htim2, &sClockSourceConfig) != HAL_OK) {
		Error_Handler();
	}
	if (HAL_TIM_PWM_Init(&htim2) != HAL_OK) {
		Error_Handler();
	}
	sMasterConfig.MasterOutputTrigger = TIM_TRGO_RESET;
	sMasterConfig.MasterSlaveMode = TIM_MASTERSLAVEMODE_DISABLE;
	if (HAL_TIMEx_MasterConfigSynchronization(&htim2, &sMasterConfig) != HAL_OK) {
		Error_Handler();
	}
	sConfigOC.OCMode = TIM_OCMODE_PWM1;
	sConfigOC.Pulse = 0;
	sConfigOC.OCPolarity = TIM_OCPOLARITY_HIGH;
	sConfigOC.OCFastMode = TIM_OCFAST_DISABLE;
	if (HAL_TIM_PWM_ConfigChannel(&htim2, &sConfigOC, TIM_CHANNEL_3) != HAL_OK) {
		Error_Handler();
	}
	HAL_TIM_MspPostInit(&htim2);
}

static void MX_TIM3_Init(void) {

	TIM_MasterConfigTypeDef sMasterConfig = {0};
	TIM_OC_InitTypeDef sConfigOC = {0};

	htim3.Instance = TIM3;
	htim3.Init.Prescaler = 0;
	htim3.Init.CounterMode = TIM_COUNTERMODE_UP;
	htim3.Init.Period = 65535;
	htim3.Init.ClockDivision = TIM_CLOCKDIVISION_DIV1;
	htim3.Init.AutoReloadPreload = TIM_AUTORELOAD_PRELOAD_DISABLE;
	if (HAL_TIM_PWM_Init(&htim3) != HAL_OK) {
		Error_Handler();
	}
	sMasterConfig.MasterOutputTrigger = TIM_TRGO_RESET;
	sMasterConfig.MasterSlaveMode = TIM_MASTERSLAVEMODE_DISABLE;
	if (HAL_TIMEx_MasterConfigSynchronization(&htim3, &sMasterConfig) != HAL_OK) {
		Error_Handler();
	}
	sConfigOC.OCMode = TIM_OCMODE_PWM1;
	sConfigOC.Pulse = 0;
	sConfigOC.OCPolarity = TIM_OCPOLARITY_HIGH;
	sConfigOC.OCFastMode = TIM_OCFAST_DISABLE;
	if (HAL_TIM_PWM_ConfigChannel(&htim3, &sConfigOC, TIM_CHANNEL_2) != HAL_OK) {
		Error_Handler();
	}
	if (HAL_TIM_PWM_ConfigChannel(&htim3, &sConfigOC, TIM_CHANNEL_3) != HAL_OK) {
		Error_Handler();
	}
	HAL_TIM_MspPostInit(&htim3);
}

static void MX_TIM6_Init(void) {

	TIM_MasterConfigTypeDef sMasterConfig = {0};

	htim6.Instance = TIM6;
	htim6.Init.Prescaler = 74;
	htim6.Init.CounterMode = TIM_COUNTERMODE_UP;
	htim6.Init.Period = 99;
	htim6.Init.AutoReloadPreload = TIM_AUTORELOAD_PRELOAD_DISABLE;
	if (HAL_TIM_Base_Init(&htim6) != HAL_OK) {
		Error_Handler();
	}
	sMasterConfig.MasterOutputTrigger = TIM_TRGO_UPDATE;
	sMasterConfig.MasterSlaveMode = TIM_MASTERSLAVEMODE_DISABLE;
	if (HAL_TIMEx_MasterConfigSynchronization(&htim6, &sMasterConfig) != HAL_OK) {
		Error_Handler();
	}
}

static void MX_TIM15_Init(void) {

	TIM_ClockConfigTypeDef sClockSourceConfig = {0};
	TIM_MasterConfigTypeDef sMasterConfig = {0};

	htim15.Instance = TIM15;
	htim15.Init.Prescaler = 119;
	htim15.Init.CounterMode = TIM_COUNTERMODE_UP;
	htim15.Init.Period = 59;
	htim15.Init.ClockDivision = TIM_CLOCKDIVISION_DIV1;
	htim15.Init.RepetitionCounter = 0;
	htim15.Init.AutoReloadPreload = TIM_AUTORELOAD_PRELOAD_DISABLE;
	if (HAL_TIM_Base_Init(&htim15) != HAL_OK) {
		Error_Handler();
	}
	sClockSourceConfig.ClockSource = TIM_CLOCKSOURCE_INTERNAL;
	if (HAL_TIM_ConfigClockSource(&htim15, &sClockSourceConfig) != HAL_OK) {
		Error_Handler();
	}
	sMasterConfig.MasterOutputTrigger = TIM_TRGO_RESET;
	sMasterConfig.MasterSlaveMode = TIM_MASTERSLAVEMODE_DISABLE;
	if (HAL_TIMEx_MasterConfigSynchronization(&htim15, &sMasterConfig) != HAL_OK) {
		Error_Handler();
	}
}

static void MX_USB_OTG_FS_USB_Init(void) {

}

static void MX_DMA_Init(void) {

	/* DMA controller clock enable */
	__HAL_RCC_DMAMUX1_CLK_ENABLE();
	__HAL_RCC_DMA1_CLK_ENABLE();

	/* DMA interrupt init */
	/* DMA1_Channel1_IRQn interrupt configuration */
	HAL_NVIC_SetPriority(DMA1_Channel1_IRQn, 0, 0);
	HAL_NVIC_EnableIRQ(DMA1_Channel1_IRQn);
	/* DMA1_Channel2_IRQn interrupt configuration */
	HAL_NVIC_SetPriority(DMA1_Channel2_IRQn, 0, 0);
	HAL_NVIC_EnableIRQ(DMA1_Channel2_IRQn);
	/* DMA1_Channel3_IRQn interrupt configuration */
	HAL_NVIC_SetPriority(DMA1_Channel3_IRQn, 0, 0);
	HAL_NVIC_EnableIRQ(DMA1_Channel3_IRQn);
	/* DMA1_Channel4_IRQn interrupt configuration */
	HAL_NVIC_SetPriority(DMA1_Channel4_IRQn, 0, 0);
	HAL_NVIC_EnableIRQ(DMA1_Channel4_IRQn);
	/* DMA1_Channel5_IRQn interrupt configuration */
	HAL_NVIC_SetPriority(DMA1_Channel5_IRQn, 1, 0);
	HAL_NVIC_EnableIRQ(DMA1_Channel5_IRQn);
}

static void MX_GPIO_Init(void) {
	GPIO_InitTypeDef GPIO_InitStruct = {0};

	/* GPIO Ports Clock Enable */
	__HAL_RCC_GPIOE_CLK_ENABLE();
	__HAL_RCC_GPIOC_CLK_ENABLE();
	__HAL_RCC_GPIOF_CLK_ENABLE();
	__HAL_RCC_GPIOH_CLK_ENABLE();
	__HAL_RCC_GPIOA_CLK_ENABLE();
	__HAL_RCC_GPIOB_CLK_ENABLE();
	__HAL_RCC_GPIOG_CLK_ENABLE();
	__HAL_RCC_GPIOD_CLK_ENABLE();
	HAL_PWREx_EnableVddIO2();

	/*Configure GPIO pin Output Level */
	HAL_GPIO_WritePin(GPIOA, GPIO_PIN_0 | GPIO_PIN_1 | TFT_CS_Pin, GPIO_PIN_RESET);

	/*Configure GPIO pin Output Level */
	HAL_GPIO_WritePin(GPIOF, GPIO_PIN_12 | GPIO_PIN_13 | GPIO_PIN_14 | GPIO_PIN_15, GPIO_PIN_RESET);

	/*Configure GPIO pin Output Level */
	HAL_GPIO_WritePin(GPIOG, GPIO_PIN_0, GPIO_PIN_RESET);

	/*Configure GPIO pin Output Level */
	HAL_GPIO_WritePin(GPIOG, GPIO_PIN_1, GPIO_PIN_SET);

	/*Configure GPIO pin Output Level */
	HAL_GPIO_WritePin(GPIOD,
					  GPIO_PIN_8 | GPIO_PIN_10 | GPIO_PIN_11 | GPIO_PIN_12 | GPIO_PIN_13 | GPIO_PIN_14 | GPIO_PIN_15,
					  GPIO_PIN_RESET);

	/*Configure GPIO pin Output Level */
	HAL_GPIO_WritePin(SD_CS_GPIO_Port, SD_CS_Pin, GPIO_PIN_SET);

	/*Configure GPIO pin Output Level */
	HAL_GPIO_WritePin(TOF_TRIGGER_GPIO_Port, TOF_TRIGGER_Pin, GPIO_PIN_RESET);

	/*Configure GPIO pins : PA0 PA1 */
	GPIO_InitStruct.Pin = GPIO_PIN_0 | GPIO_PIN_1;
	GPIO_InitStruct.Mode = GPIO_MODE_OUTPUT_PP;
	GPIO_InitStruct.Pull = GPIO_NOPULL;
	GPIO_InitStruct.Speed = GPIO_SPEED_FREQ_LOW;
	HAL_GPIO_Init(GPIOA, &GPIO_InitStruct);

	/*Configure GPIO pin : TFT_CS_Pin */
	GPIO_InitStruct.Pin = TFT_CS_Pin;
	GPIO_InitStruct.Mode = GPIO_MODE_OUTPUT_PP;
	GPIO_InitStruct.Pull = GPIO_NOPULL;
	GPIO_InitStruct.Speed = GPIO_SPEED_FREQ_HIGH;
	HAL_GPIO_Init(TFT_CS_GPIO_Port, &GPIO_InitStruct);

	/*Configure GPIO pins : PF12 PF13 PF14 PF15 */
	GPIO_InitStruct.Pin = GPIO_PIN_12 | GPIO_PIN_13 | GPIO_PIN_14 | GPIO_PIN_15;
	GPIO_InitStruct.Mode = GPIO_MODE_OUTPUT_PP;
	GPIO_InitStruct.Pull = GPIO_NOPULL;
	GPIO_InitStruct.Speed = GPIO_SPEED_FREQ_VERY_HIGH;
	HAL_GPIO_Init(GPIOF, &GPIO_InitStruct);

	/*Configure GPIO pins : PG0 PG1 */
	GPIO_InitStruct.Pin = GPIO_PIN_0 | GPIO_PIN_1;
	GPIO_InitStruct.Mode = GPIO_MODE_OUTPUT_PP;
	GPIO_InitStruct.Pull = GPIO_NOPULL;
	GPIO_InitStruct.Speed = GPIO_SPEED_FREQ_VERY_HIGH;
	HAL_GPIO_Init(GPIOG, &GPIO_InitStruct);

	/*Configure GPIO pin : PB14 */
	GPIO_InitStruct.Pin = GPIO_PIN_14;
	GPIO_InitStruct.Mode = GPIO_MODE_INPUT;
	GPIO_InitStruct.Pull = GPIO_NOPULL;
	HAL_GPIO_Init(GPIOB, &GPIO_InitStruct);

	/*Configure GPIO pins : PD8 PD10 PD11 PD12
							 PD13 PD14 PD15 */
	GPIO_InitStruct.Pin =
		GPIO_PIN_8 | GPIO_PIN_10 | GPIO_PIN_11 | GPIO_PIN_12 | GPIO_PIN_13 | GPIO_PIN_14 | GPIO_PIN_15;
	GPIO_InitStruct.Mode = GPIO_MODE_OUTPUT_PP;
	GPIO_InitStruct.Pull = GPIO_NOPULL;
	GPIO_InitStruct.Speed = GPIO_SPEED_FREQ_VERY_HIGH;
	HAL_GPIO_Init(GPIOD, &GPIO_InitStruct);

	/*Configure GPIO pin : PD9 */
	GPIO_InitStruct.Pin = GPIO_PIN_9;
	GPIO_InitStruct.Mode = GPIO_MODE_INPUT;
	GPIO_InitStruct.Pull = GPIO_NOPULL;
	HAL_GPIO_Init(GPIOD, &GPIO_InitStruct);

	/*Configure GPIO pins : PA8 PA10 PA11 PA12 */
	GPIO_InitStruct.Pin = GPIO_PIN_8 | GPIO_PIN_10 | GPIO_PIN_11 | GPIO_PIN_12;
	GPIO_InitStruct.Mode = GPIO_MODE_AF_PP;
	GPIO_InitStruct.Pull = GPIO_NOPULL;
	GPIO_InitStruct.Speed = GPIO_SPEED_FREQ_VERY_HIGH;
	GPIO_InitStruct.Alternate = GPIO_AF10_OTG_FS;
	HAL_GPIO_Init(GPIOA, &GPIO_InitStruct);

	/*Configure GPIO pin : PA9 */
	GPIO_InitStruct.Pin = GPIO_PIN_9;
	GPIO_InitStruct.Mode = GPIO_MODE_INPUT;
	GPIO_InitStruct.Pull = GPIO_NOPULL;
	HAL_GPIO_Init(GPIOA, &GPIO_InitStruct);

	/*Configure GPIO pin : TOF_ECHO_Pin */
	GPIO_InitStruct.Pin = TOF_ECHO_Pin;
	GPIO_InitStruct.Mode = GPIO_MODE_IT_RISING_FALLING;
	GPIO_InitStruct.Pull = GPIO_NOPULL;
	HAL_GPIO_Init(TOF_ECHO_GPIO_Port, &GPIO_InitStruct);

	/*Configure GPIO pin : SD_CS_Pin */
	GPIO_InitStruct.Pin = SD_CS_Pin;
	GPIO_InitStruct.Mode = GPIO_MODE_OUTPUT_PP;
	GPIO_InitStruct.Pull = GPIO_PULLUP;
	GPIO_InitStruct.Speed = GPIO_SPEED_FREQ_HIGH;
	HAL_GPIO_Init(SD_CS_GPIO_Port, &GPIO_InitStruct);

	/*Configure GPIO pin : TOF_TRIGGER_Pin */
	GPIO_InitStruct.Pin = TOF_TRIGGER_Pin;
	GPIO_InitStruct.Mode = GPIO_MODE_OUTPUT_PP;
	GPIO_InitStruct.Pull = GPIO_NOPULL;
	GPIO_InitStruct.Speed = GPIO_SPEED_FREQ_LOW;
	HAL_GPIO_Init(TOF_TRIGGER_GPIO_Port, &GPIO_InitStruct);

	/*Configure GPIO pin : PE0 */
	GPIO_InitStruct.Pin = GPIO_PIN_0;
	GPIO_InitStruct.Mode = GPIO_MODE_INPUT;
	GPIO_InitStruct.Pull = GPIO_NOPULL;
	HAL_GPIO_Init(GPIOE, &GPIO_InitStruct);

	/* EXTI interrupt init*/
	HAL_NVIC_SetPriority(EXTI15_10_IRQn, 0, 0);
	HAL_NVIC_EnableIRQ(EXTI15_10_IRQn);

}

void Error_Handler(void) {
	__disable_irq();
	while (1) {
	}
}
